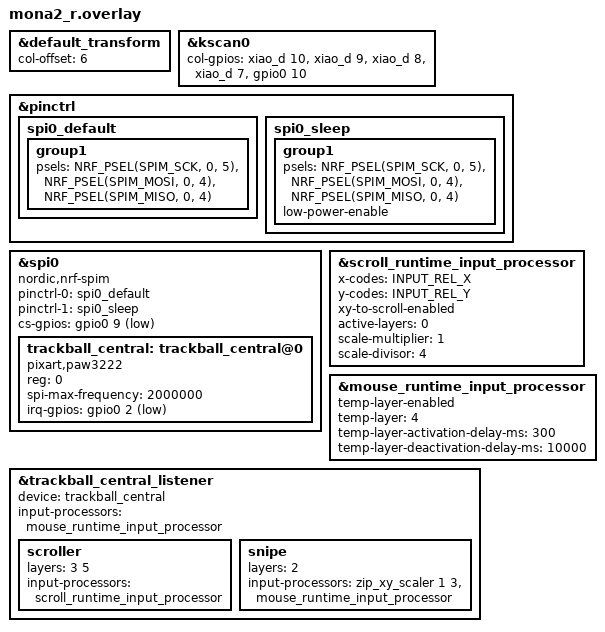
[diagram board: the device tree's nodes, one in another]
#include "mona2.dtsi"
/* mona2.dtsi 内で RC(row,col) のマトリクス展開が終わった後に include する
   (runtime-input-processor.dtsi が modifiers.h 経由で RC(keycode) を再定義するため) */
#include <input/processors/runtime-input-processor.dtsi>
#include <input/processors.dtsi>
#include <zephyr/dt-bindings/input/input-event-codes.h>

&default_transform {
    col-offset = <6>;
};

&kscan0 {
    col-gpios
        = <&xiao_d 10 GPIO_ACTIVE_HIGH>
        , <&xiao_d 9 GPIO_ACTIVE_HIGH>
        , <&xiao_d 8 GPIO_ACTIVE_HIGH>
        , <&xiao_d 7 GPIO_ACTIVE_HIGH>
        , <&gpio0 10 GPIO_ACTIVE_HIGH>
        ;
};

&pinctrl {
    spi0_default: spi0_default {
        group1 {
            psels = <NRF_PSEL(SPIM_SCK, 0, 5)>,
                    <NRF_PSEL(SPIM_MOSI, 0, 4)>,
                    <NRF_PSEL(SPIM_MISO, 0, 4)>;
        };
    };

    spi0_sleep: spi0_sleep {
        group1 {
            psels = <NRF_PSEL(SPIM_SCK, 0, 5)>,
                    <NRF_PSEL(SPIM_MOSI, 0, 4)>,
                    <NRF_PSEL(SPIM_MISO, 0, 4)>;
            low-power-enable;
        };
    };
};

&spi0 {
    status = "okay";
    compatible = "nordic,nrf-spim";
    pinctrl-0 = <&spi0_default>;
    pinctrl-1 = <&spi0_sleep>;
    pinctrl-names = "default", "sleep";
    cs-gpios = <&gpio0 9 GPIO_ACTIVE_LOW>;

    /* PAW3222 専用。ドライバには軸の反転・入れ替えの設定が無いので、
       向きは下の &mouse_runtime_input_processor（x-invert / y-invert /
       xy-swap-enabled / rotation-degrees）か DYA Studio で合わせる。
       res-cpi を書かなければセンサーの既定の CPI のまま。 */
    trackball_central: trackball_central@0 {
        status = "okay";
        compatible = "pixart,paw3222";
        reg = <0>;
        spi-max-frequency = <2000000>;
        irq-gpios = <&gpio0 2 (GPIO_ACTIVE_LOW | GPIO_PULL_UP)>; /* P0.02 (MOTION) */
    };
};

/* ─────────────────────────────────────────────────────────────
   トラックボールのレイヤーごとの動き（roBa に合わせている）
   ・オートマウス: ボールを動かすとレイヤー 4（MOUSE）に入り、ボールを止めて
     10 秒たつか、MOUSE レイヤーで &trans のキーを押すまで続く
   ・LANG1 長押し（レイヤー 3 ARROW）: ボールで縦横にスクロール
   ・SPACE 長押し（レイヤー 2 NUM）: カーソルが 1/3 の速さ（細かい位置合わせ用）
   ここに書いた値は初期値で、DYA Studio で変更して保存した値があればそちらが使われる
   ────────────────────────────────────────────────────── */

/* スクロール: トラックボールの生の動き（REL_X/Y）を xy-to-scroll-enabled でホイールに変える。
   どのレイヤーで使うかは下の scroller 子ノードで決めるので、active-layers は 0（制限しない） */
&scroll_runtime_input_processor {
    x-codes = <INPUT_REL_X>;
    y-codes = <INPUT_REL_Y>;
    xy-to-scroll-enabled;
    active-layers = <0>;
    scale-multiplier = <1>;
    scale-divisor = <4>;            /* スクロール速度。大きいほど遅い。Studioで調整可 */
    /* 軸ロック(縦のみ等)が欲しければ AXIS_SNAP_MODE_Y を初期値に */
    /* #include <dt-bindings/zmk/runtime_input_processor.h> 必要 */
    /* axis-snap-mode = <2>; */
    /* axis-snap-threshold = <100>; */
};

/* オートマウス */
&mouse_runtime_input_processor {
    temp-layer-enabled;
    temp-layer = <4>;
    /* キーコードを送るキーを押してから 300 ms は、ボールが動いてもレイヤーを有効にしない
       （入力中に手が触れて入るのを減らす）。&lt の長押しとマウスボタンは数えない */
    temp-layer-activation-delay-ms = <300>;
    /* カーソルを最後に動かしてから 10 秒で解除する（クリックや LANG1 のスクロールでは延びない）。
       DYA Studio のスライダーは 2000 ms までなので、この長さはここでしか指定できない */
    temp-layer-deactivation-delay-ms = <10000>;
};

/* 入力リスナー
   ・ふだんは mouse だけを通す（オートマウスもここで動く）
   ・レイヤー 3・5 では scroller、レイヤー 2 では snipe の処理に置き換える。
     scroller には mouse を通さないので、スクロール中にオートマウスに入らない。
     子ノードのレイヤーは固定で、DYA Studio からは変えられない */
&trackball_central_listener {
    status = "okay";
    device = <&trackball_central>;
    input-processors = <&mouse_runtime_input_processor>;

    scroller {
        layers = <3 5>;
        input-processors = <&scroll_runtime_input_processor>;
    };

    snipe {
        layers = <2>;
        input-processors = <&zip_xy_scaler 1 3>, <&mouse_runtime_input_processor>;
    };
};
